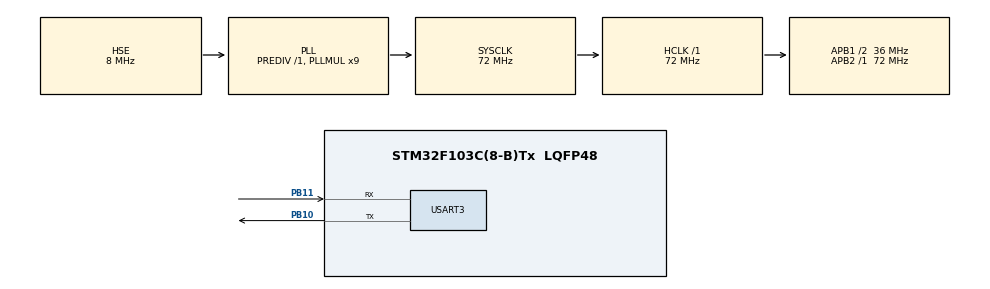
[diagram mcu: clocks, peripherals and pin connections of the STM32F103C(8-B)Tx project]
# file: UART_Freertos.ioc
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Dma.Request0=USART3_RX
Dma.USART3_RX.0.Direction=DMA_PERIPH_TO_MEMORY
Dma.USART3_RX.0.Instance=DMA1_Channel3
Dma.USART3_RX.0.MemDataAlignment=DMA_MDATAALIGN_BYTE
Dma.USART3_RX.0.MemInc=DMA_MINC_ENABLE
Dma.USART3_RX.0.Mode=DMA_NORMAL
Dma.USART3_RX.0.PeriphDataAlignment=DMA_PDATAALIGN_BYTE
Dma.USART3_RX.0.PeriphInc=DMA_PINC_DISABLE
Dma.USART3_RX.0.Priority=DMA_PRIORITY_LOW
FREERTOS.Queues01=Uart_Queue,16,uint16_t,0,Dynamic,NULL,NULL
FREERTOS.Tasks01=defaultTask,24,128,StartDefaultTask,Default,NULL,Dynamic,NULL,NULL;UART_task,8,256,startUART_task,Default,NULL,Dynamic,NULL,NULL
Mcu.Family=STM32F1
Mcu.Name=STM32F103C(8-B)Tx
Mcu.Package=LQFP48
NVIC.DMA1_Channel3_IRQn=true\:5\:0\:false\:false\:true\:true\:false\:true\:true
NVIC.PriorityGroup=NVIC_PRIORITYGROUP_4
NVIC.TIM4_IRQn=true\:15\:0\:false\:false\:true\:false\:false\:true\:true
NVIC.TimeBase=TIM4_IRQn
NVIC.TimeBaseIP=TIM4
NVIC.USART3_IRQn=true\:5\:0\:false\:false\:true\:true\:true\:true\:true
PA13.Mode=Serial_Wire
PA13.Signal=SYS_JTMS-SWDIO
PA14.Mode=Serial_Wire
PA14.Signal=SYS_JTCK-SWCLK
PB10.Mode=Asynchronous
PB10.Signal=USART3_TX
PB11.Mode=Asynchronous
PB11.Signal=USART3_RX
PD0-OSC_IN.Mode=HSE-External-Oscillator
PD0-OSC_IN.Signal=RCC_OSC_IN
PD1-OSC_OUT.Mode=HSE-External-Oscillator
PD1-OSC_OUT.Signal=RCC_OSC_OUT
ProjectManager.HeapSize=0x200
ProjectManager.StackSize=0x400
ProjectManager.TargetToolchain=CMake
RCC.AHBFreq_Value=72000000
RCC.APB1CLKDivider=RCC_HCLK_DIV2
RCC.APB1Freq_Value=36000000
RCC.APB1TimFreq_Value=72000000
RCC.APB2Freq_Value=72000000
RCC.APB2TimFreq_Value=72000000
RCC.HCLKFreq_Value=72000000
RCC.PLLMUL=RCC_PLL_MUL9
RCC.PLLSourceVirtual=RCC_PLLSOURCE_HSE
RCC.SYSCLKFreq_VALUE=72000000
RCC.SYSCLKSource=RCC_SYSCLKSOURCE_PLLCLK
RCC.USBFreq_Value=72000000
USART3.VirtualMode=VM_ASYNC
VP_FREERTOS_VS_CMSIS_V2.Mode=CMSIS_V2
VP_SYS_VS_tim4.Mode=TIM4
board=custom

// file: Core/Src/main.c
/* USER CODE BEGIN Header */
/**
  ******************************************************************************
  * @file           : main.c
  * @brief          : Main program body
  ******************************************************************************
  * @attention
  *
  * Copyright (c) 2025 STMicroelectronics.
  * All rights reserved.
  *
  * This software is licensed under terms that can be found in the LICENSE file
  * in the root directory of this software component.
  * If no LICENSE file comes with this software, it is provided AS-IS.
  *
  ******************************************************************************
  */
/* USER CODE END Header */
#include "main.h"
#include "cmsis_os.h"
#include "dma.h"
#include "usart.h"
#include "gpio.h"

/* USER CODE BEGIN Includes */
#include <string.h>
/* USER CODE END Includes */

void SystemClock_Config(void);
void MX_FREERTOS_Init(void);

int main(void)
{

  /* MCU Configuration--------------------------------------------------------*/

  /* Reset of all peripherals, Initializes the Flash interface and the Systick. */
  HAL_Init();

  /* Configure the system clock */
  SystemClock_Config();

  /* Initialize all configured peripherals */
  MX_GPIO_Init();
  MX_DMA_Init();
  MX_USART3_UART_Init();
  /* USER CODE BEGIN 2 */

  // 测试UART是否工作 - 在FreeRTOS启动前发送测试消息

  /* USER CODE END 2 */

  /* Init scheduler */
  osKernelInitialize();  /* Call init function for freertos objects (in cmsis_os2.c) */
  MX_FREERTOS_Init();

  /* Start scheduler */
  osKernelStart();

  /* We should never get here as control is now taken by the scheduler */

  /* Infinite loop */
  while (1)
  {

  }
}

void SystemClock_Config(void)
{
  RCC_OscInitTypeDef RCC_OscInitStruct = {0};
  RCC_ClkInitTypeDef RCC_ClkInitStruct = {0};

  /** Initializes the RCC Oscillators according to the specified parameters
  * in the RCC_OscInitTypeDef structure.
  */
  RCC_OscInitStruct.OscillatorType = RCC_OSCILLATORTYPE_HSE;
  RCC_OscInitStruct.HSEState = RCC_HSE_ON;
  RCC_OscInitStruct.HSEPredivValue = RCC_HSE_PREDIV_DIV1;
  RCC_OscInitStruct.HSIState = RCC_HSI_ON;
  RCC_OscInitStruct.PLL.PLLState = RCC_PLL_ON;
  RCC_OscInitStruct.PLL.PLLSource = RCC_PLLSOURCE_HSE;
  RCC_OscInitStruct.PLL.PLLMUL = RCC_PLL_MUL9;
  if (HAL_RCC_OscConfig(&RCC_OscInitStruct) != HAL_OK)
  {
    Error_Handler();
  }

  /** Initializes the CPU, AHB and APB buses clocks
  */
  RCC_ClkInitStruct.ClockType = RCC_CLOCKTYPE_HCLK|RCC_CLOCKTYPE_SYSCLK
                              |RCC_CLOCKTYPE_PCLK1|RCC_CLOCKTYPE_PCLK2;
  RCC_ClkInitStruct.SYSCLKSource = RCC_SYSCLKSOURCE_PLLCLK;
  RCC_ClkInitStruct.AHBCLKDivider = RCC_SYSCLK_DIV1;
  RCC_ClkInitStruct.APB1CLKDivider = RCC_HCLK_DIV2;
  RCC_ClkInitStruct.APB2CLKDivider = RCC_HCLK_DIV1;

  if (HAL_RCC_ClockConfig(&RCC_ClkInitStruct, FLASH_LATENCY_2) != HAL_OK)
  {
    Error_Handler();
  }
}

void HAL_TIM_PeriodElapsedCallback(TIM_HandleTypeDef *htim)
{
  if (htim->Instance == TIM4)
  {
    HAL_IncTick();
  }
}

void Error_Handler(void)
{
  __disable_irq();
  while (1)
  {
  }
}

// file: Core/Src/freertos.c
/* USER CODE BEGIN Header */
/**
  ******************************************************************************
  * File Name          : freertos.c
  * Description        : Code for freertos applications
  ******************************************************************************
  * @attention
  *
  * Copyright (c) 2025 STMicroelectronics.
  * All rights reserved.
  *
  * This software is licensed under terms that can be found in the LICENSE file
  * in the root directory of this software component.
  * If no LICENSE file comes with this software, it is provided AS-IS.
  *
  ******************************************************************************
  */
/* USER CODE END Header */

#include "FreeRTOS.h"
#include "task.h"
#include "main.h"
#include "cmsis_os.h"

/* USER CODE BEGIN Includes */
#include "usart.h"
#include <string.h>
#include <stdio.h>
#include "dma.h"
#include "stream_buffer.h"

/* 外部变量声明 */
extern DMA_HandleTypeDef hdma_usart3_rx;
/* USER CODE END Includes */

/* USER CODE BEGIN Variables */
// DMA接收相关变量
#define DMA_RX_BUF_SIZE 128
uint8_t dma_rx_buf[DMA_RX_BUF_SIZE];  // DMA接收缓冲区

// 流缓冲区相关变量
#define STREAM_BUFFER_SIZE 512
#define STREAM_TRIGGER_LEVEL 1          // 触发级别：收到1个字节就唤醒任务
StreamBufferHandle_t uart_stream_buffer;       // 流缓冲区句柄
/* USER CODE END Variables */
/* Definitions for defaultTask */
osThreadId_t defaultTaskHandle;
const osThreadAttr_t defaultTask_attributes = {
  .name = "defaultTask",
  .stack_size = 128 * 4,
  .priority = (osPriority_t) osPriorityNormal,
};
/* Definitions for UART_task */
osThreadId_t UART_taskHandle;
const osThreadAttr_t UART_task_attributes = {
  .name = "UART_task",
  .stack_size = 256 * 4,
  .priority = (osPriority_t) osPriorityLow,
};
/* Definitions for Uart_Queue */
osMessageQueueId_t Uart_QueueHandle;
const osMessageQueueAttr_t Uart_Queue_attributes = {
  .name = "Uart_Queue"
};

/* USER CODE BEGIN FunctionPrototypes */
void process_uart_data(uint8_t* data, size_t length);
void check_task_stack_usage(void);
/* USER CODE END FunctionPrototypes */

void StartDefaultTask(void *argument);
void startUART_task(void *argument);

void MX_FREERTOS_Init(void); /* (MISRA C 2004 rule 8.1) */

void MX_FREERTOS_Init(void) {
  /* USER CODE BEGIN Init */
  // 检查初始堆内存
  uint32_t free_heap_before = xPortGetFreeHeapSize();

  // 创建流缓冲区
  uart_stream_buffer = xStreamBufferCreate(STREAM_BUFFER_SIZE, STREAM_TRIGGER_LEVEL);

  // 检查流缓冲区是否创建成功
  if (uart_stream_buffer == NULL) {
    // 流缓冲区创建失败 - 可能内存不足
    Error_Handler();
  }

  // 启动DMA + Idle中断接收
  HAL_UARTEx_ReceiveToIdle_DMA(&huart3, dma_rx_buf, DMA_RX_BUF_SIZE);

  // 禁用DMA的半完成中断（只保留完成中断和Idle中断）
  __HAL_DMA_DISABLE_IT(&hdma_usart3_rx, DMA_IT_HT);
  /* USER CODE END Init */

  /* Create the queue(s) */
  /* creation of Uart_Queue */
  Uart_QueueHandle = osMessageQueueNew (16, sizeof(uint16_t), &Uart_Queue_attributes);

  /* Create the thread(s) */
  /* creation of defaultTask */
  defaultTaskHandle = osThreadNew(StartDefaultTask, NULL, &defaultTask_attributes);

  /* creation of UART_task */
  UART_taskHandle = osThreadNew(startUART_task, NULL, &UART_task_attributes);

}

void StartDefaultTask(void *argument)
{
  for(;;)
  {
    osDelay(1);
  }
}

void startUART_task(void *argument)
{
  /* USER CODE BEGIN startUART_task */
  /* 发送欢迎信息 */
  char welcome[] = "=== Simple Stream Buffer Echo ===\r\n"
                   "Commands:\r\n"
                   "  'stack' - Show task stack usage\r\n"
                   "  Other text will be echoed\r\n"
                   "Type something:\r\n";
  HAL_UART_Transmit(&huart3, (uint8_t*)welcome, strlen(welcome), 1000);

  uint8_t rx_buffer[128];
  size_t bytes_read;

  /* Infinite loop */
  for(;;)
  {
    /* 从流缓冲区接收数据 - 阻塞等待 */
    bytes_read = xStreamBufferReceive(uart_stream_buffer,
                                    rx_buffer,
                                    sizeof(rx_buffer) - 1,
                                    portMAX_DELAY);

    if (bytes_read > 0) {
      rx_buffer[bytes_read] = '\0';
      process_uart_data(rx_buffer, bytes_read);
    }
  }
  osdelay(10);
  /* USER CODE END startUART_task */
}

/* USER CODE BEGIN Application */

/**
 * @brief UART接收事件回调函数（DMA + Idle中断）- 最简版本
 * @param huart: UART句柄
 * @param Size: 接收到的数据长度
 * @retval None
 */
void HAL_UARTEx_RxEventCallback(UART_HandleTypeDef *huart, uint16_t Size)
{
  if (huart->Instance == USART3) {
    BaseType_t xHigherPriorityTaskWoken = pdFALSE;

    /* 将DMA接收到的数据发送到流缓冲区 */
    xStreamBufferSendFromISR(uart_stream_buffer,
                           dma_rx_buf,
                           Size,
                           &xHigherPriorityTaskWoken);

    /* 重新启动DMA接收 */
    HAL_UARTEx_ReceiveToIdle_DMA(&huart3, dma_rx_buf, DMA_RX_BUF_SIZE);
    __HAL_DMA_DISABLE_IT(&hdma_usart3_rx, DMA_IT_HT);

    /* 执行任务切换 */
    portYIELD_FROM_ISR(xHigherPriorityTaskWoken);
  }
}

/**
 * @brief UART错误回调函数
 * @param huart: UART句柄
 * @retval None
 */
void HAL_UART_ErrorCallback(UART_HandleTypeDef *huart)
{
  if (huart->Instance == USART3) {
    /* 发生错误时重新启动DMA接收 */
    HAL_UARTEx_ReceiveToIdle_DMA(&huart3, dma_rx_buf, DMA_RX_BUF_SIZE);
    __HAL_DMA_DISABLE_IT(&hdma_usart3_rx, DMA_IT_HT);
  }
}

/**
 * @brief 处理UART接收到的数据 - 最简版本
 * @param data: 接收到的数据
 * @param length: 数据长度
 * @retval None
 */
void process_uart_data(uint8_t* data, size_t length)
{
  /* 检查是否是查看栈使用情况的命令 */
  if (strncmp((char*)data, "stack", 5) == 0) {
    check_task_stack_usage();
    return;
  }

  /* 简单回显 */
  HAL_UART_Transmit(&huart3, (uint8_t*)"Echo: ", 6, 100);
  HAL_UART_Transmit(&huart3, data, length, 100);
  HAL_UART_Transmit(&huart3, (uint8_t*)"\r\n", 2, 100);
}

/**
 * @brief 检查当前UART任务栈使用情况
 * @retval None
 */
void check_task_stack_usage(void)
{
  /* 获取当前UART任务的栈剩余空间 */
  UBaseType_t stack_remaining = uxTaskGetStackHighWaterMark(UART_taskHandle);

  /* 计算栈使用情况 - 使用正确的栈大小 */
  uint32_t total_stack = 256 * 4;  // 总栈大小784字节 (与UART_task_attributes一致)
  uint32_t used_stack = total_stack - (stack_remaining * sizeof(StackType_t));
  uint32_t usage_percent = (used_stack * 100) / total_stack;

  /* 简单输出 */
  char info[100];
  int len = sprintf(info,
    "\r\nUART Task Stack: %lu/%lu bytes (%lu%% used)\r\n\r\n",
    used_stack, total_stack, usage_percent);

  HAL_UART_Transmit(&huart3, (uint8_t*)info, len, 500);
}

/* USER CODE END Application */
